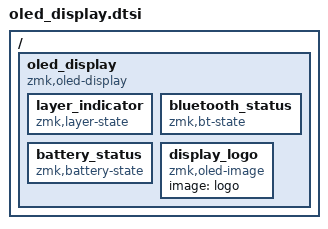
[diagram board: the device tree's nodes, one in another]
/ {
    oled_display {
        compatible = "zmk,oled-display";

        layer_indicator {
            compatible = "zmk,layer-state";
        };

        bluetooth_status {
            compatible = "zmk,bt-state";
        };

        battery_status {
            compatible = "zmk,battery-state";
        };

        display_logo {
            compatible = "zmk,oled-image";
            image = <&logo>;
        };
    };
};
